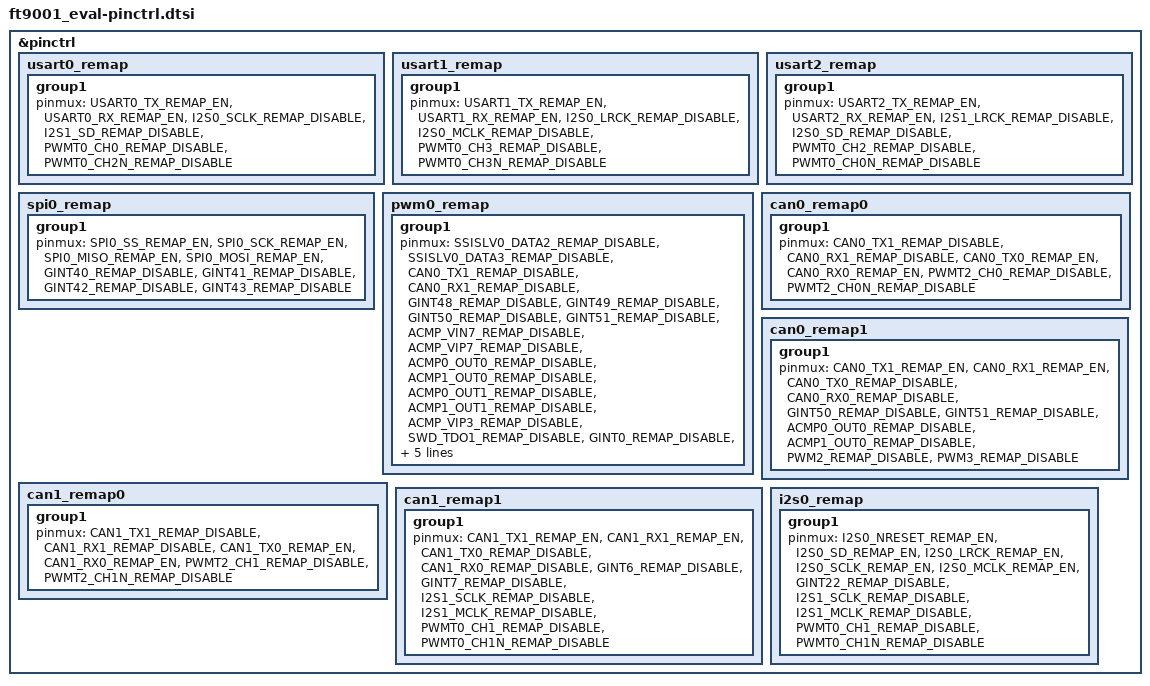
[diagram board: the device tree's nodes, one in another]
/*
 * Copyright (c) 2025 Focaltech Systems CO.,Ltd
 * SPDX-License-Identifier: Apache-2.0
 */

#include <dt-bindings/pinctrl/ft9001-pinctrl.h>

&pinctrl {
	
  usart0_remap: usart0_remap {
		group1 {
			pinmux = <USART0_TX_REMAP_EN>, <USART0_RX_REMAP_EN>,<I2S0_SCLK_REMAP_DISABLE>, <I2S1_SD_REMAP_DISABLE>, <PWMT0_CH0_REMAP_DISABLE>, <PWMT0_CH2N_REMAP_DISABLE>;
		};
	};
 	
  usart1_remap: usart1_remap {
		group1 {
			pinmux = <USART1_TX_REMAP_EN>, <USART1_RX_REMAP_EN>,<I2S0_LRCK_REMAP_DISABLE>, <I2S0_MCLK_REMAP_DISABLE>, <PWMT0_CH3_REMAP_DISABLE>, <PWMT0_CH3N_REMAP_DISABLE>;
		};
	};
 
  usart2_remap: usart2_remap {
		group1 {
			pinmux = <USART2_TX_REMAP_EN>, <USART2_RX_REMAP_EN>,<I2S1_LRCK_REMAP_DISABLE>, <I2S0_SD_REMAP_DISABLE>, <PWMT0_CH2_REMAP_DISABLE>, <PWMT0_CH0N_REMAP_DISABLE>;
		};
	};
	
  spi0_remap: spi0_remap {
  group1 {
			pinmux = <SPI0_SS_REMAP_EN>, <SPI0_SCK_REMAP_EN>, <SPI0_MISO_REMAP_EN>, <SPI0_MOSI_REMAP_EN>, <GINT40_REMAP_DISABLE>, <GINT41_REMAP_DISABLE>, <GINT42_REMAP_DISABLE>, <GINT43_REMAP_DISABLE>;
		};
  };

  pwm0_remap: pwm0_remap{
  group1 {
            pinmux = <SSISLV0_DATA2_REMAP_DISABLE>, <SSISLV0_DATA3_REMAP_DISABLE>,<CAN0_TX1_REMAP_DISABLE>, <CAN0_RX1_REMAP_DISABLE>,
                <GINT48_REMAP_DISABLE>, <GINT49_REMAP_DISABLE>, <GINT50_REMAP_DISABLE>, <GINT51_REMAP_DISABLE>,
                <ACMP_VIN7_REMAP_DISABLE>, <ACMP_VIP7_REMAP_DISABLE>, <ACMP0_OUT0_REMAP_DISABLE>, <ACMP1_OUT0_REMAP_DISABLE>,
                <ACMP0_OUT1_REMAP_DISABLE>, <ACMP1_OUT1_REMAP_DISABLE>, <ACMP_VIP3_REMAP_DISABLE>, <SWD_TDO1_REMAP_DISABLE>,
                <GINT0_REMAP_DISABLE>, <GINT3_REMAP_DISABLE>, <GINT4_REMAP_DISABLE>, <GINT5_REMAP_DISABLE>,
                <PWM0_REMAP_EN>, <PWM1_REMAP_EN>, <PWM2_REMAP_EN>, <PWM3_REMAP_EN>,
                <PWM4_REMAP_EN>, <PWM5_REMAP_EN>, <PWM6_REMAP_EN>, <PWM7_REMAP_EN>;
        };
};

can0_remap0: can0_remap0{
group1 {
          pinmux = <CAN0_TX1_REMAP_DISABLE>, <CAN0_RX1_REMAP_DISABLE>, <CAN0_TX0_REMAP_EN>, <CAN0_RX0_REMAP_EN>,
              <PWMT2_CH0_REMAP_DISABLE>, <PWMT2_CH0N_REMAP_DISABLE>;
      };
};

can0_remap1: can0_remap1{
group1 {
          pinmux = <CAN0_TX1_REMAP_EN>, <CAN0_RX1_REMAP_EN>, <CAN0_TX0_REMAP_DISABLE>, <CAN0_RX0_REMAP_DISABLE>,
              <GINT50_REMAP_DISABLE>, <GINT51_REMAP_DISABLE>, <ACMP0_OUT0_REMAP_DISABLE>, <ACMP1_OUT0_REMAP_DISABLE>,
               <PWM2_REMAP_DISABLE>, <PWM3_REMAP_DISABLE>;
      };
};

can1_remap0: can1_remap0{
group1 {
          pinmux = <CAN1_TX1_REMAP_DISABLE>, <CAN1_RX1_REMAP_DISABLE>, <CAN1_TX0_REMAP_EN>, <CAN1_RX0_REMAP_EN>,
              <PWMT2_CH1_REMAP_DISABLE>, <PWMT2_CH1N_REMAP_DISABLE>;
      };
};

can1_remap1: can1_remap1{
group1 {
          pinmux = <CAN1_TX1_REMAP_EN>, <CAN1_RX1_REMAP_EN>, <CAN1_TX0_REMAP_DISABLE>, <CAN1_RX0_REMAP_DISABLE>,
              <GINT6_REMAP_DISABLE>, <GINT7_REMAP_DISABLE>, <I2S1_SCLK_REMAP_DISABLE>, <I2S1_MCLK_REMAP_DISABLE>,
               <PWMT0_CH1_REMAP_DISABLE>, <PWMT0_CH1N_REMAP_DISABLE>;
      };
};

i2s0_remap: i2s0_remap{
group1 {
          pinmux = <I2S0_NRESET_REMAP_EN>, <I2S0_SD_REMAP_EN>, <I2S0_LRCK_REMAP_EN>, <I2S0_SCLK_REMAP_EN>,
              <I2S0_MCLK_REMAP_EN>, <GINT22_REMAP_DISABLE>, <I2S1_SCLK_REMAP_DISABLE>, <I2S1_MCLK_REMAP_DISABLE>,
               <PWMT0_CH1_REMAP_DISABLE>, <PWMT0_CH1N_REMAP_DISABLE>;
      };
};
    
 status = "okay";
};


